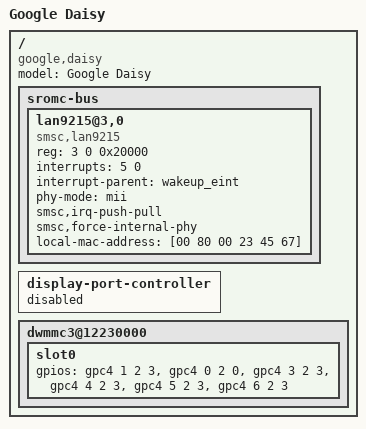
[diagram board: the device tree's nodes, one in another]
/*
 * Google Daisy board device tree source
 *
 * Copyright (c) 2012 Google, Inc
 *
 * This program is free software; you can redistribute it and/or modify
 * it under the terms of the GNU General Public License version 2 as
 * published by the Free Software Foundation.
*/

/dts-v1/;
/include/ "exynos5250.dtsi"
/include/ "cros5250-common.dtsi"

/ {
	model = "Google Daisy";
	compatible = "google,daisy", "samsung,exynos5250";

	sromc-bus {
		lan9215@3,0 {
			compatible = "smsc,lan9215", "smsc,lan9115";
			reg = <3 0 0x20000>;
			interrupts = <5 0>;
			interrupt-parent = <&wakeup_eint>;
			phy-mode = "mii";
			smsc,irq-push-pull;
			smsc,force-internal-phy;
			local-mac-address = [00 80 00 23 45 67];
		};
	};

	display-port-controller {
		status = "disabled";
	};

	/*
	 * On Daisy WiFi hooks up through a connector so keep a high drive
	 * strength for safety.
	 *
	 * TODO: Test various drive strengths and see what's really needed
	 */
	dwmmc3@12230000 {
		slot0 {
			gpios = <&gpc4 1 2 3 3>, <&gpc4 0 2 0 3>,
				<&gpc4 3 2 3 3>, <&gpc4 4 2 3 3>,
				<&gpc4 5 2 3 3>, <&gpc4 6 2 3 3>;
		};
	};
};
